VERSION ""

NS_ :

BS_:

BU_: XXX

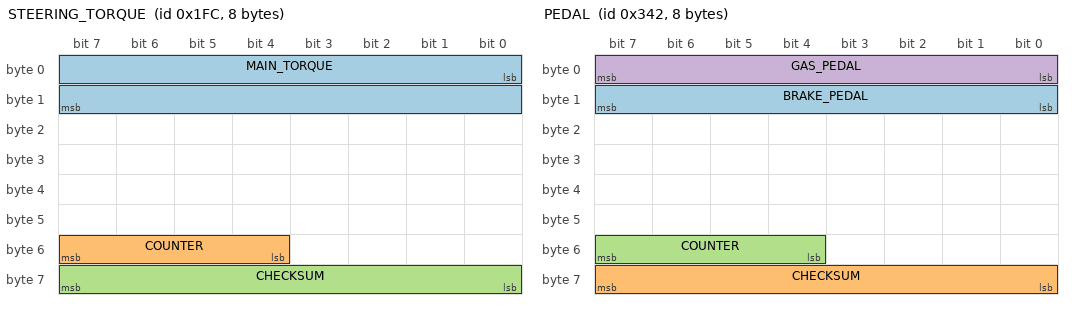
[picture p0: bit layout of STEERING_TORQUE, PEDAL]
BO_ 508 STEERING_TORQUE: 8 XXX
 SG_ MAIN_TORQUE : 0|16@1- (0.1,0) [0|65535] "" XXX
 SG_ COUNTER : 55|4@0+ (1,0) [0|15] "" XXX
 SG_ CHECKSUM : 56|8@1+ (1,0) [0|255] "" XXX

BO_ 482 STEERING_MODULE_ADAS: 8 XXX
 SG_ STEER_ANGLE : 24|16@1- (0.1,0) [0|255] "" XXX
 SG_ COUNTER : 55|4@0+ (1,0) [0|15] "" XXX
 SG_ CHECKSUM : 56|8@1+ (1,0) [0|255] "" XXX
 SG_ SET_ME_FF : 47|8@0+ (1,0) [0|255] "" XXX
 SG_ SET_ME_F : 48|4@1+ (1,0) [0|15] "" XXX
 SG_ STEER_CMD : 0|20@1- (0.1,0) [0|65535] "" XXX
 SG_ STEER_REQ : 21|1@0+ (1,0) [0|1] "" XXX
 SG_ UNKNOWN : 22|2@0+ (1,0) [0|3] "" XXX

BO_ 834 PEDAL: 8 XXX
 SG_ BRAKE_PEDAL : 8|8@1+ (0.01,0) [0|255] "" XXX
 SG_ CHECKSUM : 56|8@1+ (1,0) [0|255] "" XXX
 SG_ COUNTER : 55|4@0+ (1,0) [0|15] "" XXX
 SG_ GAS_PEDAL : 0|8@1+ (0.01,0) [0|255] "" XXX

BO_ 660 SEATBELT: 8 XXX
 SG_ SEATBELT_DRIVER : 17|1@0+ (1,0) [0|1] "" XXX

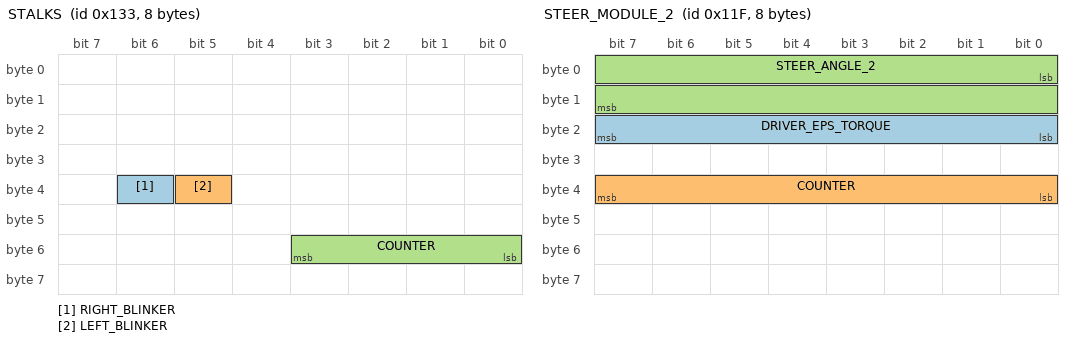
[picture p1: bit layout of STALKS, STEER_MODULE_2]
BO_ 307 STALKS: 8 XXX
 SG_ RIGHT_BLINKER : 38|1@0+ (1,0) [0|1] "" XXX
 SG_ LEFT_BLINKER : 37|1@0+ (1,0) [0|1] "" XXX
 SG_ COUNTER : 48|4@1+ (1,0) [0|15] "" XXX

BO_ 287 STEER_MODULE_2: 8 XXX
 SG_ DRIVER_EPS_TORQUE : 16|8@1+ (1,0) [0|255] "" XXX
 SG_ COUNTER : 39|8@0+ (1,0) [0|255] "" XXX
 SG_ STEER_ANGLE_2 : 0|16@1- (0.1,0) [0|65535] "" XXX

BO_ 944 PCM_BUTTONS: 8 XXX

BO_ 544 PEDAL_PRESSED: 8 XXX
 SG_ PEDAL_PRESSED_ACTIVE_LOW : 12|1@0+ (1,0) [0|1] "" XXX

BO_ 578 DRIVE_STATE: 8 XXX
 SG_ BRAKE_PRESSED : 37|1@0+ (1,0) [0|1] "" XXX
 SG_ GEAR : 40|3@1+ (1,0) [0|7] "" XXX

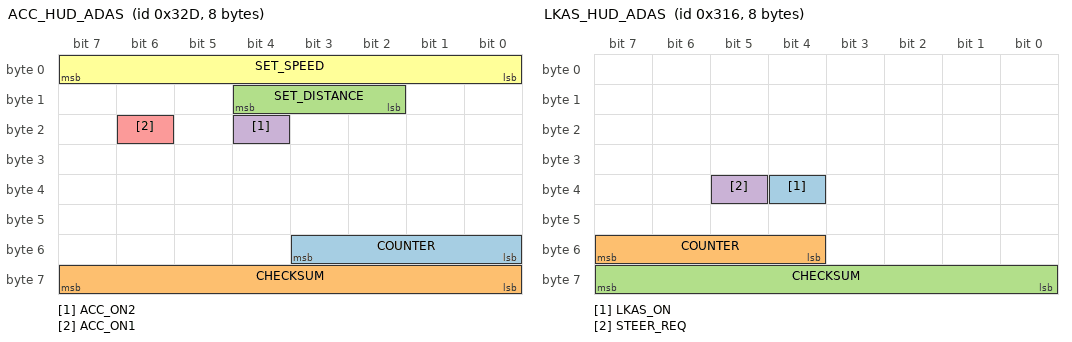
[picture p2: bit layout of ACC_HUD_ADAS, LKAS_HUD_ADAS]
BO_ 813 ACC_HUD_ADAS: 8 XXX
 SG_ COUNTER : 48|4@1+ (1,0) [0|15] "" XXX
 SG_ CHECKSUM : 56|8@1+ (1,0) [0|255] "" XXX
 SG_ SET_DISTANCE : 12|3@0+ (1,0) [0|7] "" XXX
 SG_ ACC_ON2 : 20|1@0+ (1,0) [0|1] "" XXX
 SG_ ACC_ON1 : 22|1@0+ (1,0) [0|1] "" XXX
 SG_ SET_SPEED : 0|8@1+ (0.5,0) [0|255] "" XXX

BO_ 790 LKAS_HUD_ADAS: 8 XXX
 SG_ LKAS_ON : 36|1@0+ (1,0) [0|1] "" XXX
 SG_ COUNTER : 55|4@0+ (1,0) [0|15] "" XXX
 SG_ CHECKSUM : 63|8@0+ (1,0) [0|255] "" XXX
 SG_ STEER_REQ : 37|1@0+ (1,0) [0|1] "" XXX

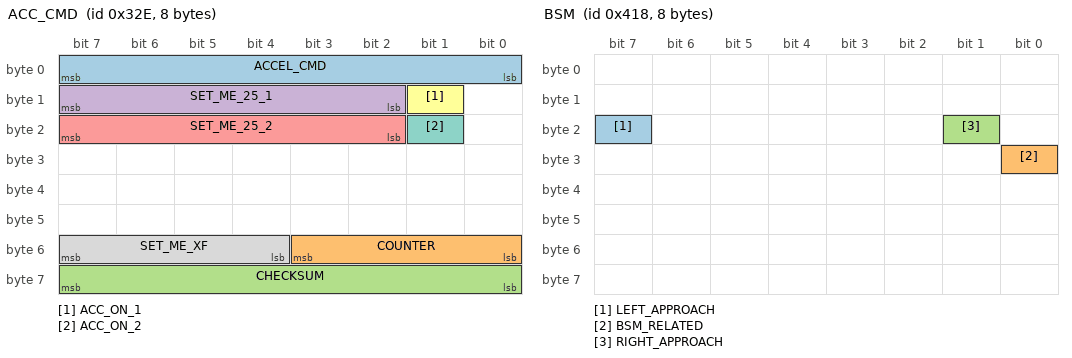
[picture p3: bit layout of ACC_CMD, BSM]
BO_ 814 ACC_CMD: 8 XXX
 SG_ ACCEL_CMD : 0|8@1+ (1,-98) [0|255] "" XXX
 SG_ COUNTER : 48|4@1+ (1,0) [0|15] "" XXX
 SG_ CHECKSUM : 56|8@1+ (1,0) [0|255] "" XXX
 SG_ SET_ME_25_1 : 10|6@1+ (1,0) [0|255] "" XXX
 SG_ SET_ME_25_2 : 18|6@1+ (1,0) [0|255] "" XXX
 SG_ ACC_ON_1 : 9|1@0+ (1,0) [0|1] "" XXX
 SG_ ACC_ON_2 : 17|1@0+ (1,0) [0|1] "" XXX
 SG_ SET_ME_XF : 55|4@0+ (1,0) [0|15] "" XXX

BO_ 1048 BSM: 8 XXX
 SG_ LEFT_APPROACH : 23|1@0+ (1,0) [0|1] "" XXX
 SG_ BSM_RELATED : 24|1@0+ (1,0) [0|1] "" XXX
 SG_ RIGHT_APPROACH : 17|1@0+ (1,0) [0|1] "" XXX

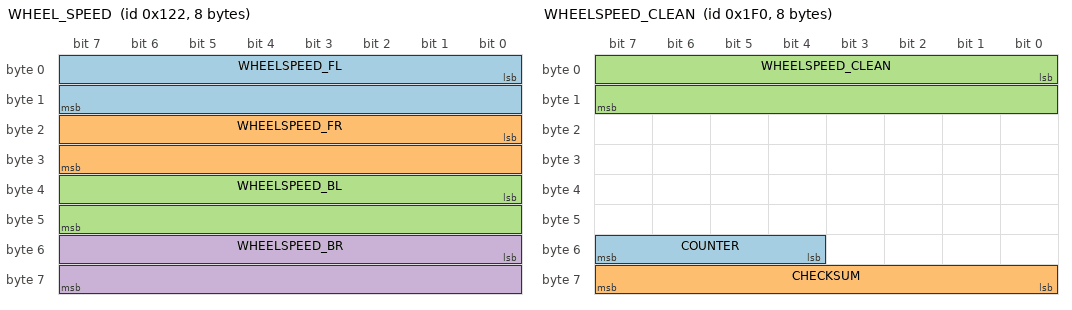
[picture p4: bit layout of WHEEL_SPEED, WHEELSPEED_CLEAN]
BO_ 290 WHEEL_SPEED: 8 XXX
 SG_ WHEELSPEED_FL : 0|16@1- (0.1,0) [0|65535] "" XXX
 SG_ WHEELSPEED_FR : 16|16@1+ (0.1,0) [0|65535] "" XXX
 SG_ WHEELSPEED_BL : 32|16@1+ (0.1,0) [0|65535] "" XXX
 SG_ WHEELSPEED_BR : 48|16@1+ (0.1,0) [0|65535] "" XXX

BO_ 496 WHEELSPEED_CLEAN: 8 XXX
 SG_ COUNTER : 55|4@0+ (1,0) [0|15] "" XXX
 SG_ CHECKSUM : 56|8@1+ (1,0) [0|255] "" XXX
 SG_ WHEELSPEED_CLEAN : 0|16@1+ (0.1,0) [0|65535] "" XXX

BO_ 692 ADAS2: 8 XXX

BO_ 815 ADAS3: 8 XXX

BO_ 843 ADAS4: 8 XXX

BO_ 884 ADAS5: 8 XXX

BO_ 1074 ADAS6: 8 XXX

VAL_ 578 GEAR 4 "D" 2 "R" 1 "P" ;
VAL_ 813 SET_DISTANCE 8 "4bar" 4 "3bar" 2 "2bar" 1 "1bar" ;
